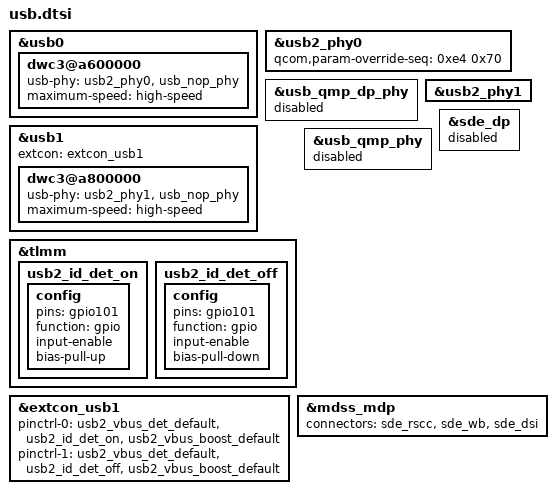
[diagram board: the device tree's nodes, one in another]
/*
 * nubia overrides dts
 */

&usb0 {
	dwc3@a600000 {
		usb-phy = <&usb2_phy0>, <&usb_nop_phy>;
		maximum-speed = "high-speed";
	};
};

&usb2_phy0 {
	qcom,param-override-seq = <0xe4 0x70>;
};

&usb_qmp_dp_phy {
	status = "disabled";
};

&usb1 {
	extcon = <&extcon_usb1>;
	status = "ok";
	dwc3@a800000 {
		usb-phy = <&usb2_phy1>, <&usb_nop_phy>;
		maximum-speed = "high-speed";
	};
};

&tlmm {
	usb2_id_det_on: usb2_id_det_on {
		config {
			pins = "gpio101";
			function = "gpio";
			input-enable;
			bias-pull-up;
		};
	};
        usb2_id_det_off: usb2_id_det_off {
                config {
			pins = "gpio101";
			function = "gpio";
			input-enable;
			bias-pull-down;
		};
	};
};

&extcon_usb1 {
	pinctrl-names = "default", "sleep";
	pinctrl-0 = <&usb2_vbus_det_default
		     &usb2_id_det_on
		     &usb2_vbus_boost_default>;
	pinctrl-1 = <&usb2_vbus_det_default
		     &usb2_id_det_off
		     &usb2_vbus_boost_default>;
};

&usb2_phy1 {
	status = "ok";
};

&usb_qmp_phy {
        status = "disabled";
};

&sde_dp {
	status = "disabled";
};

&mdss_mdp {
	connectors = <&sde_rscc &sde_wb &sde_dsi>;
};
